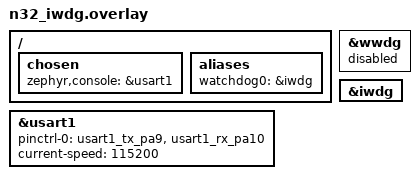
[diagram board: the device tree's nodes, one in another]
/* SPDX-License-Identifier: Apache-2.0 */

/ {
	chosen {
		zephyr,console = &usart1;
	};

	aliases {
		watchdog0 = &iwdg;
	};
};

&usart1 {
	pinctrl-0 = <&usart1_tx_pa9 &usart1_rx_pa10>;
	pinctrl-names = "default";
	current-speed = <115200>;
	status = "okay";
};

&wwdg {
	status = "disabled";
};

&iwdg {
	status = "okay";
};
